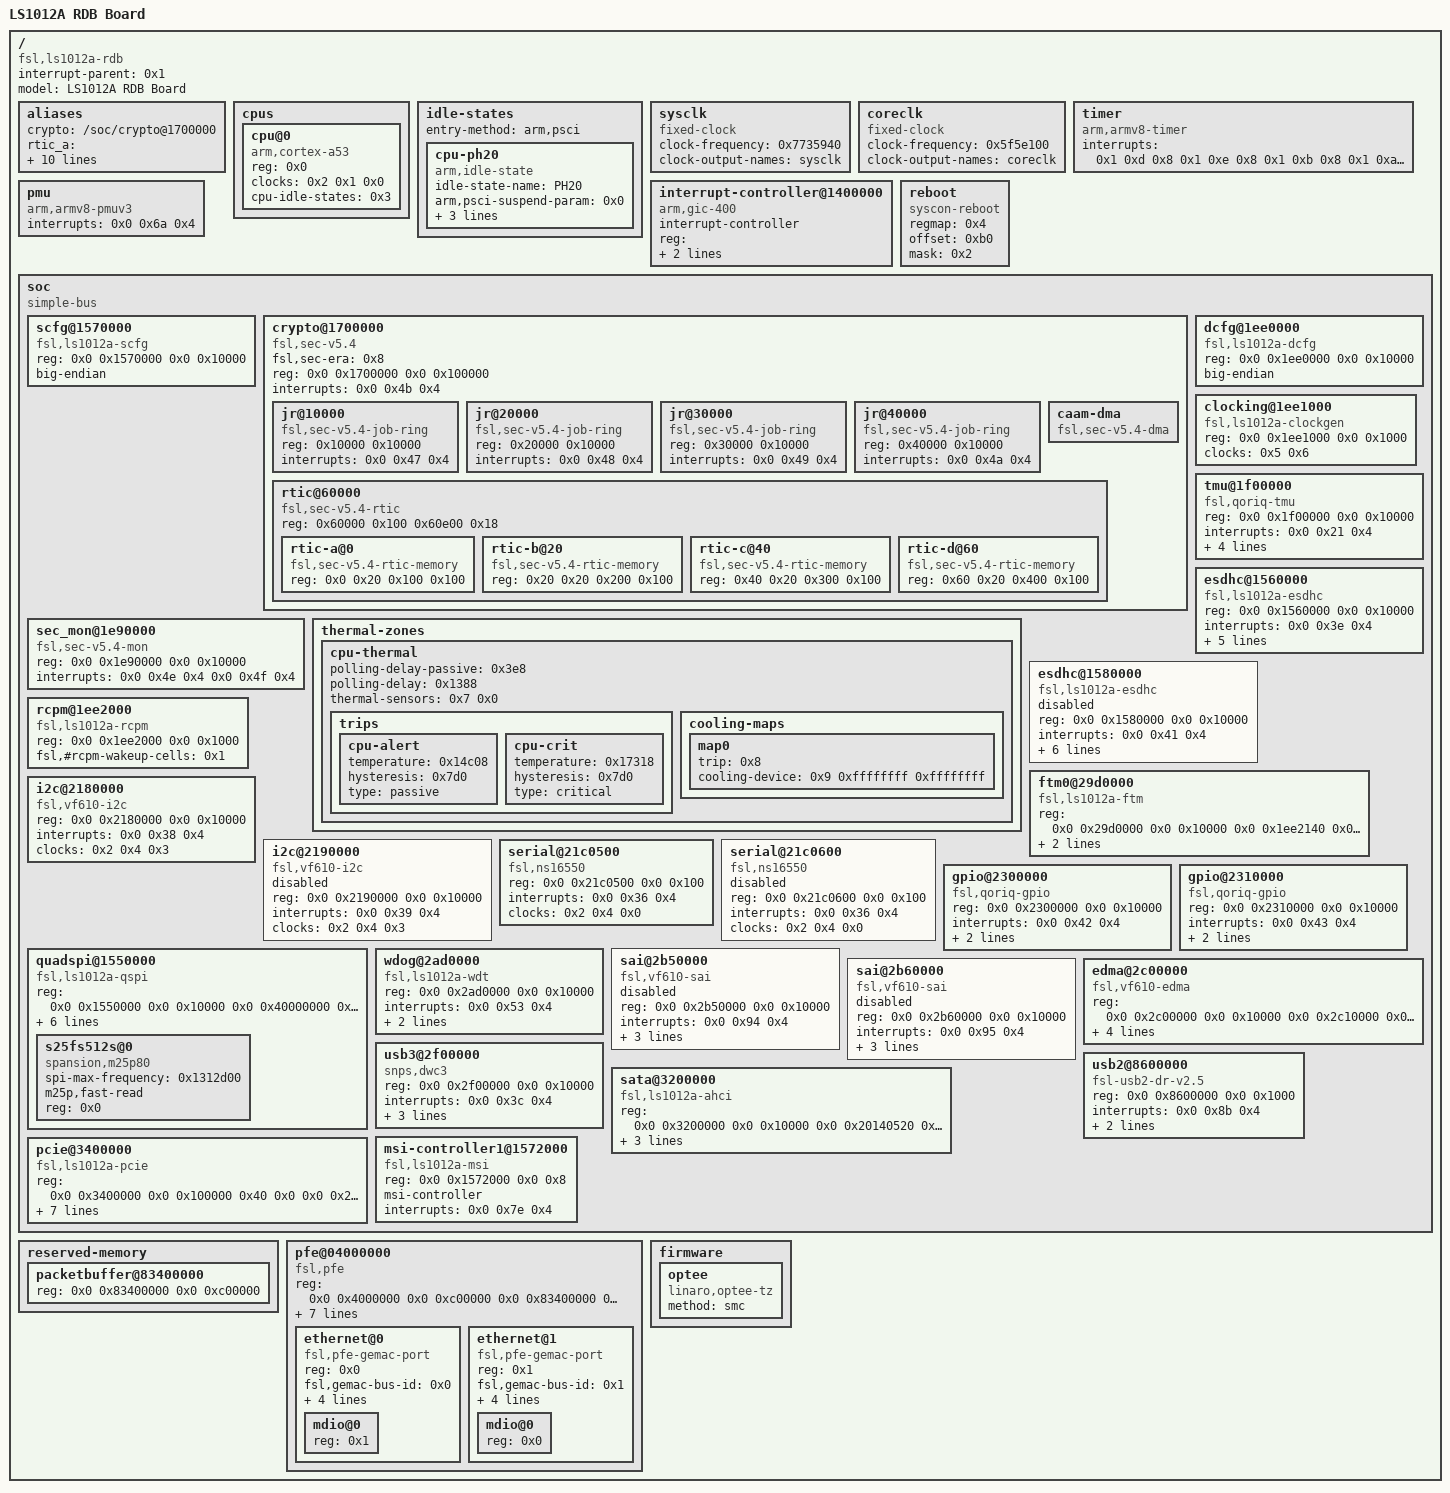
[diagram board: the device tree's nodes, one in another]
/dts-v1/;

/ {
	compatible = "fsl,ls1012a-rdb", "fsl,ls1012a";
	interrupt-parent = <0x1>;
	#address-cells = <0x2>;
	#size-cells = <0x2>;
	model = "LS1012A RDB Board";

	aliases {
		crypto = "/soc/crypto@1700000";
		rtic_a = "/soc/crypto@1700000/rtic@60000/rtic-a@0";
		rtic_b = "/soc/crypto@1700000/rtic@60000/rtic-b@20";
		rtic_c = "/soc/crypto@1700000/rtic@60000/rtic-c@40";
		rtic_d = "/soc/crypto@1700000/rtic@60000/rtic-d@60";
		sec_mon = "/soc/sec_mon@1e90000";
		ethernet0 = "/pfe@04000000/ethernet@0";
		ethernet1 = "/pfe@04000000/ethernet@1";
	};

	cpus {
		#address-cells = <0x1>;
		#size-cells = <0x0>;

		cpu@0 {
			device_type = "cpu";
			compatible = "arm,cortex-a53";
			reg = <0x0>;
			clocks = <0x2 0x1 0x0>;
			#cooling-cells = <0x2>;
			cpu-idle-states = <0x3>;
			linux,phandle = <0x9>;
			phandle = <0x9>;
		};
	};

	idle-states {
		entry-method = "arm,psci";

		cpu-ph20 {
			compatible = "arm,idle-state";
			idle-state-name = "PH20";
			arm,psci-suspend-param = <0x0>;
			entry-latency-us = <0x3e8>;
			exit-latency-us = <0x3e8>;
			min-residency-us = <0xbb8>;
			linux,phandle = <0x3>;
			phandle = <0x3>;
		};
	};

	sysclk {
		compatible = "fixed-clock";
		#clock-cells = <0x0>;
		clock-frequency = <0x7735940>;
		clock-output-names = "sysclk";
		linux,phandle = <0x5>;
		phandle = <0x5>;
	};

	coreclk {
		compatible = "fixed-clock";
		#clock-cells = <0x0>;
		clock-frequency = <0x5f5e100>;
		clock-output-names = "coreclk";
		linux,phandle = <0x6>;
		phandle = <0x6>;
	};

	timer {
		compatible = "arm,armv8-timer";
		interrupts = <0x1 0xd 0x8 0x1 0xe 0x8 0x1 0xb 0x8 0x1 0xa 0x8>;
	};

	pmu {
		compatible = "arm,armv8-pmuv3";
		interrupts = <0x0 0x6a 0x4>;
	};

	interrupt-controller@1400000 {
		compatible = "arm,gic-400";
		#interrupt-cells = <0x3>;
		interrupt-controller;
		reg = <0x0 0x1401000 0x0 0x1000 0x0 0x1402000 0x0 0x2000 0x0 0x1404000 0x0 0x2000 0x0 0x1406000 0x0 0x2000>;
		interrupts = <0x1 0x9 0x8>;
		linux,phandle = <0x1>;
		phandle = <0x1>;
	};

	reboot {
		compatible = "syscon-reboot";
		regmap = <0x4>;
		offset = <0xb0>;
		mask = <0x2>;
	};

	soc {
		compatible = "simple-bus";
		#address-cells = <0x2>;
		#size-cells = <0x2>;
		ranges;

		scfg@1570000 {
			compatible = "fsl,ls1012a-scfg", "syscon";
			reg = <0x0 0x1570000 0x0 0x10000>;
			big-endian;
			linux,phandle = <0xd>;
			phandle = <0xd>;
		};

		crypto@1700000 {
			compatible = "fsl,sec-v5.4", "fsl,sec-v5.0", "fsl,sec-v4.0";
			fsl,sec-era = <0x8>;
			#address-cells = <0x1>;
			#size-cells = <0x1>;
			ranges = <0x0 0x0 0x1700000 0x100000>;
			reg = <0x0 0x1700000 0x0 0x100000>;
			interrupts = <0x0 0x4b 0x4>;

			jr@10000 {
				compatible = "fsl,sec-v5.4-job-ring", "fsl,sec-v5.0-job-ring", "fsl,sec-v4.0-job-ring";
				reg = <0x10000 0x10000>;
				interrupts = <0x0 0x47 0x4>;
			};

			jr@20000 {
				compatible = "fsl,sec-v5.4-job-ring", "fsl,sec-v5.0-job-ring", "fsl,sec-v4.0-job-ring";
				reg = <0x20000 0x10000>;
				interrupts = <0x0 0x48 0x4>;
			};

			jr@30000 {
				compatible = "fsl,sec-v5.4-job-ring", "fsl,sec-v5.0-job-ring", "fsl,sec-v4.0-job-ring";
				reg = <0x30000 0x10000>;
				interrupts = <0x0 0x49 0x4>;
			};

			jr@40000 {
				compatible = "fsl,sec-v5.4-job-ring", "fsl,sec-v5.0-job-ring", "fsl,sec-v4.0-job-ring";
				reg = <0x40000 0x10000>;
				interrupts = <0x0 0x4a 0x4>;
			};

			caam-dma {
				compatible = "fsl,sec-v5.4-dma", "fsl,sec-v5.0-dma", "fsl,sec-v4.0-dma";
			};

			rtic@60000 {
				compatible = "fsl,sec-v5.4-rtic", "fsl,sec-v5.0-rtic", "fsl,sec-v4.0-rtic";
				#address-cells = <0x1>;
				#size-cells = <0x1>;
				reg = <0x60000 0x100 0x60e00 0x18>;
				ranges = <0x0 0x60100 0x500>;

				rtic-a@0 {
					compatible = "fsl,sec-v5.4-rtic-memory", "fsl,sec-v5.0-rtic-memory", "fsl,sec-v4.0-rtic-memory";
					reg = <0x0 0x20 0x100 0x100>;
				};

				rtic-b@20 {
					compatible = "fsl,sec-v5.4-rtic-memory", "fsl,sec-v5.0-rtic-memory", "fsl,sec-v4.0-rtic-memory";
					reg = <0x20 0x20 0x200 0x100>;
				};

				rtic-c@40 {
					compatible = "fsl,sec-v5.4-rtic-memory", "fsl,sec-v5.0-rtic-memory", "fsl,sec-v4.0-rtic-memory";
					reg = <0x40 0x20 0x300 0x100>;
				};

				rtic-d@60 {
					compatible = "fsl,sec-v5.4-rtic-memory", "fsl,sec-v5.0-rtic-memory", "fsl,sec-v4.0-rtic-memory";
					reg = <0x60 0x20 0x400 0x100>;
				};
			};
		};

		sec_mon@1e90000 {
			compatible = "fsl,sec-v5.4-mon", "fsl,sec-v5.0-mon", "fsl,sec-v4.0-mon";
			reg = <0x0 0x1e90000 0x0 0x10000>;
			interrupts = <0x0 0x4e 0x4 0x0 0x4f 0x4>;
		};

		dcfg@1ee0000 {
			compatible = "fsl,ls1012a-dcfg", "syscon";
			reg = <0x0 0x1ee0000 0x0 0x10000>;
			big-endian;
			linux,phandle = <0x4>;
			phandle = <0x4>;
		};

		clocking@1ee1000 {
			compatible = "fsl,ls1012a-clockgen";
			reg = <0x0 0x1ee1000 0x0 0x1000>;
			#clock-cells = <0x2>;
			clocks = <0x5 0x6>;
			clock-names = "sysclk", "coreclk";
			linux,phandle = <0x2>;
			phandle = <0x2>;
		};

		tmu@1f00000 {
			compatible = "fsl,qoriq-tmu";
			reg = <0x0 0x1f00000 0x0 0x10000>;
			interrupts = <0x0 0x21 0x4>;
			fsl,tmu-range = <0xb0000 0x9002a 0x6004c 0x30062>;
			fsl,tmu-calibration = <0x0 0x26 0x1 0x2d 0x2 0x32 0x3 0x39 0x4 0x3f 0x5 0x46 0x6 0x4d 0x7 0x54 0x8 0x5a 0x9 0x61 0xa 0x6a 0xb 0x71 0x10000 0x25 0x10001 0x2c 0x10002 0x35 0x10003 0x3d 0x10004 0x45 0x10005 0x4e 0x10006 0x57 0x10007 0x61 0x10008 0x6b 0x10009 0x76 0x20000 0x29 0x20001 0x33 0x20002 0x3d 0x20003 0x49 0x20004 0x56 0x20005 0x61 0x20006 0x6d 0x30000 0x21 0x30001 0x2a 0x30002 0x3c 0x30003 0x4e>;
			big-endian;
			#thermal-sensor-cells = <0x1>;
			linux,phandle = <0x7>;
			phandle = <0x7>;
		};

		thermal-zones {

			cpu-thermal {
				polling-delay-passive = <0x3e8>;
				polling-delay = <0x1388>;
				thermal-sensors = <0x7 0x0>;

				trips {

					cpu-alert {
						temperature = <0x14c08>;
						hysteresis = <0x7d0>;
						type = "passive";
						linux,phandle = <0x8>;
						phandle = <0x8>;
					};

					cpu-crit {
						temperature = <0x17318>;
						hysteresis = <0x7d0>;
						type = "critical";
					};
				};

				cooling-maps {

					map0 {
						trip = <0x8>;
						cooling-device = <0x9 0xffffffff 0xffffffff>;
					};
				};
			};
		};

		esdhc@1560000 {
			compatible = "fsl,ls1012a-esdhc", "fsl,esdhc";
			reg = <0x0 0x1560000 0x0 0x10000>;
			interrupts = <0x0 0x3e 0x4>;
			clocks = <0x2 0x4 0x0>;
			voltage-ranges = <0x708 0x708 0xce4 0xce4>;
			sdhci,auto-cmd12;
			big-endian;
			bus-width = <0x4>;
			status = "okay";
		};

		esdhc@1580000 {
			compatible = "fsl,ls1012a-esdhc", "fsl,esdhc";
			reg = <0x0 0x1580000 0x0 0x10000>;
			interrupts = <0x0 0x41 0x4>;
			clocks = <0x2 0x4 0x0>;
			voltage-ranges = <0x708 0x708 0xce4 0xce4>;
			sdhci,auto-cmd12;
			big-endian;
			broken-cd;
			bus-width = <0x4>;
			status = "disabled";
		};

		rcpm@1ee2000 {
			compatible = "fsl,ls1012a-rcpm", "fsl,qoriq-rcpm-2.1";
			reg = <0x0 0x1ee2000 0x0 0x1000>;
			fsl,#rcpm-wakeup-cells = <0x1>;
			linux,phandle = <0xe>;
			phandle = <0xe>;
		};

		ftm0@29d0000 {
			compatible = "fsl,ls1012a-ftm";
			reg = <0x0 0x29d0000 0x0 0x10000 0x0 0x1ee2140 0x0 0x4>;
			reg-names = "ftm", "FlexTimer1";
			interrupts = <0x0 0x56 0x4>;
			big-endian;
		};

		i2c@2180000 {
			compatible = "fsl,vf610-i2c";
			#address-cells = <0x1>;
			#size-cells = <0x0>;
			reg = <0x0 0x2180000 0x0 0x10000>;
			interrupts = <0x0 0x38 0x4>;
			clocks = <0x2 0x4 0x3>;
			status = "okay";
		};

		i2c@2190000 {
			compatible = "fsl,vf610-i2c";
			#address-cells = <0x1>;
			#size-cells = <0x0>;
			reg = <0x0 0x2190000 0x0 0x10000>;
			interrupts = <0x0 0x39 0x4>;
			clocks = <0x2 0x4 0x3>;
			status = "disabled";
		};

		serial@21c0500 {
			compatible = "fsl,ns16550", "ns16550a";
			reg = <0x0 0x21c0500 0x0 0x100>;
			interrupts = <0x0 0x36 0x4>;
			clocks = <0x2 0x4 0x0>;
			status = "okay";
		};

		serial@21c0600 {
			compatible = "fsl,ns16550", "ns16550a";
			reg = <0x0 0x21c0600 0x0 0x100>;
			interrupts = <0x0 0x36 0x4>;
			clocks = <0x2 0x4 0x0>;
			status = "disabled";
		};

		gpio@2300000 {
			compatible = "fsl,qoriq-gpio";
			reg = <0x0 0x2300000 0x0 0x10000>;
			interrupts = <0x0 0x42 0x4>;
			gpio-controller;
			#gpio-cells = <0x2>;
			interrupt-controller;
			#interrupt-cells = <0x2>;
		};

		gpio@2310000 {
			compatible = "fsl,qoriq-gpio";
			reg = <0x0 0x2310000 0x0 0x10000>;
			interrupts = <0x0 0x43 0x4>;
			gpio-controller;
			#gpio-cells = <0x2>;
			interrupt-controller;
			#interrupt-cells = <0x2>;
		};

		quadspi@1550000 {
			compatible = "fsl,ls1012a-qspi", "fsl,ls1021a-qspi";
			#address-cells = <0x1>;
			#size-cells = <0x0>;
			reg = <0x0 0x1550000 0x0 0x10000 0x0 0x40000000 0x0 0x10000000>;
			reg-names = "QuadSPI", "QuadSPI-memory";
			interrupts = <0x0 0x63 0x4>;
			clock-names = "qspi_en", "qspi";
			clocks = <0x2 0x4 0x0 0x2 0x4 0x0>;
			big-endian;
			fsl,qspi-has-second-chip;
			status = "okay";
			num-cs = <0x2>;
			bus-num = <0x0>;

			s25fs512s@0 {
				compatible = "spansion,m25p80";
				#address-cells = <0x1>;
				#size-cells = <0x1>;
				spi-max-frequency = <0x1312d00>;
				m25p,fast-read;
				reg = <0x0>;
			};
		};

		wdog@2ad0000 {
			compatible = "fsl,ls1012a-wdt", "fsl,imx21-wdt";
			reg = <0x0 0x2ad0000 0x0 0x10000>;
			interrupts = <0x0 0x53 0x4>;
			clocks = <0x2 0x4 0x0>;
			big-endian;
		};

		sai@2b50000 {
			#sound-dai-cells = <0x0>;
			compatible = "fsl,vf610-sai";
			reg = <0x0 0x2b50000 0x0 0x10000>;
			interrupts = <0x0 0x94 0x4>;
			clocks = <0x2 0x4 0x3 0x2 0x4 0x3 0x2 0x4 0x3 0x2 0x4 0x3>;
			clock-names = "bus", "mclk1", "mclk2", "mclk3";
			dma-names = "tx", "rx";
			dmas = <0xa 0x1 0x2f 0xa 0x1 0x2e>;
			status = "disabled";
		};

		sai@2b60000 {
			#sound-dai-cells = <0x0>;
			compatible = "fsl,vf610-sai";
			reg = <0x0 0x2b60000 0x0 0x10000>;
			interrupts = <0x0 0x95 0x4>;
			clocks = <0x2 0x4 0x3 0x2 0x4 0x3 0x2 0x4 0x3 0x2 0x4 0x3>;
			clock-names = "bus", "mclk1", "mclk2", "mclk3";
			dma-names = "tx", "rx";
			dmas = <0xa 0x1 0x2d 0xa 0x1 0x2c>;
			status = "disabled";
		};

		edma@2c00000 {
			#dma-cells = <0x2>;
			compatible = "fsl,vf610-edma";
			reg = <0x0 0x2c00000 0x0 0x10000 0x0 0x2c10000 0x0 0x10000 0x0 0x2c20000 0x0 0x10000>;
			interrupts = <0x0 0x67 0x4 0x0 0x67 0x4>;
			interrupt-names = "edma-tx", "edma-err";
			dma-channels = <0x20>;
			big-endian;
			clock-names = "dmamux0", "dmamux1";
			clocks = <0x2 0x4 0x3 0x2 0x4 0x3>;
			linux,phandle = <0xa>;
			phandle = <0xa>;
		};

		usb3@2f00000 {
			compatible = "snps,dwc3";
			reg = <0x0 0x2f00000 0x0 0x10000>;
			interrupts = <0x0 0x3c 0x4>;
			dr_mode = "host";
			snps,quirk-frame-length-adjustment = <0x20>;
			snps,dis_rxdet_inp3_quirk;
		};

		usb2@8600000 {
			compatible = "fsl-usb2-dr-v2.5", "fsl-usb2-dr";
			reg = <0x0 0x8600000 0x0 0x1000>;
			interrupts = <0x0 0x8b 0x4>;
			dr_mode = "host";
			phy_type = "ulpi";
		};

		sata@3200000 {
			compatible = "fsl,ls1012a-ahci", "fsl,ls1043a-ahci";
			reg = <0x0 0x3200000 0x0 0x10000 0x0 0x20140520 0x0 0x4>;
			reg-names = "ahci", "sata-ecc";
			interrupts = <0x0 0x45 0x4>;
			clocks = <0x2 0x4 0x0>;
			dma-coherent;
			status = "okay";
		};

		msi-controller1@1572000 {
			compatible = "fsl,ls1012a-msi";
			reg = <0x0 0x1572000 0x0 0x8>;
			msi-controller;
			interrupts = <0x0 0x7e 0x4>;
			linux,phandle = <0xb>;
			phandle = <0xb>;
		};

		pcie@3400000 {
			compatible = "fsl,ls1012a-pcie", "snps,dw-pcie";
			reg = <0x0 0x3400000 0x0 0x100000 0x40 0x0 0x0 0x2000>;
			reg-names = "regs", "config";
			interrupts = <0x0 0x76 0x4 0x0 0x75 0x4>;
			interrupt-names = "aer", "pme";
			#address-cells = <0x3>;
			#size-cells = <0x2>;
			device_type = "pci";
			num-lanes = <0x4>;
			bus-range = <0x0 0xff>;
			ranges = <0x81000000 0x0 0x0 0x40 0x10000 0x0 0x10000 0x82000000 0x0 0x40000000 0x40 0x40000000 0x0 0x40000000>;
			msi-parent = <0xb>;
			#interrupt-cells = <0x1>;
			interrupt-map-mask = <0x0 0x0 0x0 0x7>;
			interrupt-map = <0x0 0x0 0x0 0x1 0x1 0x0 0x6e 0x4 0x0 0x0 0x0 0x2 0x1 0x0 0x6f 0x4 0x0 0x0 0x0 0x3 0x1 0x0 0x70 0x4 0x0 0x0 0x0 0x4 0x1 0x0 0x71 0x4>;
			status = "okay";
		};
	};

	reserved-memory {
		#address-cells = <0x2>;
		#size-cells = <0x2>;
		ranges;

		packetbuffer@83400000 {
			reg = <0x0 0x83400000 0x0 0xc00000>;
			linux,phandle = <0xc>;
			phandle = <0xc>;
		};
	};

	pfe@04000000 {
		compatible = "fsl,pfe";
		reg = <0x0 0x4000000 0x0 0xc00000 0x0 0x83400000 0x0 0xc00000>;
		reg-names = "pfe", "pfe-ddr";
		fsl,pfe-num-interfaces = <0x2>;
		interrupts = <0x0 0xac 0x4 0x0 0xad 0x4 0x0 0xae 0x4>;
		interrupt-names = "pfe_hif", "pfe_hif_nocpy", "pfe_wol";
		memory-region = <0xc>;
		fsl,pfe-scfg = <0xd 0x0>;
		fsl,rcpm-wakeup = <0xe 0xf0000020>;
		clocks = <0x2 0x4 0x0>;
		clock-names = "pfe";
		status = "okay";
		#address-cells = <0x1>;
		#size-cells = <0x0>;

		ethernet@0 {
			compatible = "fsl,pfe-gemac-port";
			#address-cells = <0x1>;
			#size-cells = <0x0>;
			reg = <0x0>;
			fsl,gemac-bus-id = <0x0>;
			fsl,gemac-phy-id = <0x2>;
			fsl,mdio-mux-val = <0x0>;
			phy-mode = "sgmii";
			fsl,pfe-phy-if-flags = <0x0>;

			mdio@0 {
				reg = <0x1>;
			};
		};

		ethernet@1 {
			compatible = "fsl,pfe-gemac-port";
			#address-cells = <0x1>;
			#size-cells = <0x0>;
			reg = <0x1>;
			fsl,gemac-bus-id = <0x1>;
			fsl,gemac-phy-id = <0x1>;
			fsl,mdio-mux-val = <0x0>;
			phy-mode = "rgmii-txid";
			fsl,pfe-phy-if-flags = <0x0>;

			mdio@0 {
				reg = <0x0>;
			};
		};
	};

	firmware {

		optee {
			compatible = "linaro,optee-tz";
			method = "smc";
		};
	};
};
